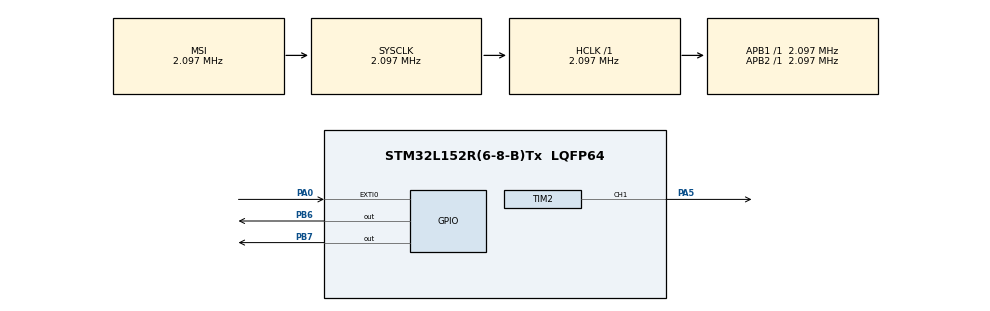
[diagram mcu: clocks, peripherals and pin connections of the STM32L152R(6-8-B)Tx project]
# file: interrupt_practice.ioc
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Mcu.Family=STM32L1
Mcu.Name=STM32L152R(6-8-B)Tx
Mcu.Package=LQFP64
NVIC.EXTI0_IRQn=true\:0\:0\:false\:false\:true\:true
NVIC.PriorityGroup=NVIC_PRIORITYGROUP_4
NVIC.TIM2_IRQn=true\:1\:0\:true\:false\:true\:true
PA0-WKUP1.Signal=GPXTI0
PA5.Signal=S_TIM2_CH1_ETR
PB6.Signal=GPIO_Output
PB7.Signal=GPIO_Output
ProjectManager.HeapSize=0x200
ProjectManager.StackSize=0x400
ProjectManager.TargetToolchain=MDK-ARM V5
RCC.AHBFreq_Value=2097000
RCC.APB1Freq_Value=2097000
RCC.APB2Freq_Value=2097000
RCC.HSE_VALUE=24000000
RCC.HSI_VALUE=16000000
RCC.LSE_VALUE=32768
RCC.MSI_VALUE=2097000
RCC.SYSCLKFreq_VALUE=2097000
RCC.VCOOutputFreq_Value=48000000
SH.S_TIM2_CH1_ETR.0=TIM2_CH1,Output Compare1 CH1
TIM2.Channel-Output\ Compare1\ CH1=TIM_CHANNEL_1
TIM2.Period=10000
TIM2.Prescaler=2000
TIM2.TIM_MasterOutputTrigger=TIM_TRGO_UPDATE
board=custom

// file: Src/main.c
/**
  ******************************************************************************
  * @file           : main.c
  * @brief          : Main program body
  ******************************************************************************
  ** This notice applies to any and all portions of this file
  * that are not between comment pairs USER CODE BEGIN and
  * USER CODE END. Other portions of this file, whether
  * inserted by the user or by software development tools
  * are owned by their respective copyright owners.
  *
  * COPYRIGHT(c) 2019 STMicroelectronics
  *
  * Redistribution and use in source and binary forms, with or without modification,
  * are permitted provided that the following conditions are met:
  *   1. Redistributions of source code must retain the above copyright notice,
  *      this list of conditions and the following disclaimer.
  *   2. Redistributions in binary form must reproduce the above copyright notice,
  *      this list of conditions and the following disclaimer in the documentation
  *      and/or other materials provided with the distribution.
  *   3. Neither the name of STMicroelectronics nor the names of its contributors
  *      may be used to endorse or promote products derived from this software
  *      without specific prior written permission.
  *
  * THIS SOFTWARE IS PROVIDED BY THE COPYRIGHT HOLDERS AND CONTRIBUTORS "AS IS"
  * AND ANY EXPRESS OR IMPLIED WARRANTIES, INCLUDING, BUT NOT LIMITED TO, THE
  * IMPLIED WARRANTIES OF MERCHANTABILITY AND FITNESS FOR A PARTICULAR PURPOSE ARE
  * DISCLAIMED. IN NO EVENT SHALL THE COPYRIGHT HOLDER OR CONTRIBUTORS BE LIABLE
  * FOR ANY DIRECT, INDIRECT, INCIDENTAL, SPECIAL, EXEMPLARY, OR CONSEQUENTIAL
  * DAMAGES (INCLUDING, BUT NOT LIMITED TO, PROCUREMENT OF SUBSTITUTE GOODS OR
  * SERVICES; LOSS OF USE, DATA, OR PROFITS; OR BUSINESS INTERRUPTION) HOWEVER
  * CAUSED AND ON ANY THEORY OF LIABILITY, WHETHER IN CONTRACT, STRICT LIABILITY,
  * OR TORT (INCLUDING NEGLIGENCE OR OTHERWISE) ARISING IN ANY WAY OUT OF THE USE
  * OF THIS SOFTWARE, EVEN IF ADVISED OF THE POSSIBILITY OF SUCH DAMAGE.
  *
  ******************************************************************************
  */
#include "main.h"
#include "stm32l1xx_hal.h"

TIM_HandleTypeDef htim2;

/* USER CODE BEGIN PV */
/* Private variables ---------------------------------------------------------*/

/* USER CODE END PV */

void SystemClock_Config(void);
static void MX_GPIO_Init(void);
static void MX_TIM2_Init(void);
void HAL_TIM_MspPostInit(TIM_HandleTypeDef *htim);

/* USER CODE BEGIN PFP */
/* Private function prototypes -----------------------------------------------*/

/* USER CODE END PFP */

/* USER CODE BEGIN 0 */
uint8_t lyr = 0;
/* USER CODE END 0 */

int main(void)
{

  /* MCU Configuration----------------------------------------------------------*/

  /* Reset of all peripherals, Initializes the Flash interface and the Systick. */
  HAL_Init();

  /* Configure the system clock */
  SystemClock_Config();

  /* Initialize all configured peripherals */
  MX_GPIO_Init();
  MX_TIM2_Init();
  /* USER CODE BEGIN 2 */

	HAL_TIM_Base_Start_IT(&htim2);

  /* USER CODE END 2 */

  /* Infinite loop */
  /* USER CODE BEGIN WHILE */
  while (1)
  {
	HAL_GPIO_TogglePin(GPIOB, GPIO_PIN_7);
	HAL_Delay(500);
  /* USER CODE END WHILE */

  }

}

void SystemClock_Config(void)
{

  RCC_OscInitTypeDef RCC_OscInitStruct;
  RCC_ClkInitTypeDef RCC_ClkInitStruct;

    /**Configure the main internal regulator output voltage
    */
  __HAL_PWR_VOLTAGESCALING_CONFIG(PWR_REGULATOR_VOLTAGE_SCALE1);

    /**Initializes the CPU, AHB and APB busses clocks
    */
  RCC_OscInitStruct.OscillatorType = RCC_OSCILLATORTYPE_MSI;
  RCC_OscInitStruct.MSIState = RCC_MSI_ON;
  RCC_OscInitStruct.MSICalibrationValue = 0;
  RCC_OscInitStruct.MSIClockRange = RCC_MSIRANGE_5;
  RCC_OscInitStruct.PLL.PLLState = RCC_PLL_NONE;
  if (HAL_RCC_OscConfig(&RCC_OscInitStruct) != HAL_OK)
  {
    _Error_Handler(__FILE__, __LINE__);
  }

    /**Initializes the CPU, AHB and APB busses clocks
    */
  RCC_ClkInitStruct.ClockType = RCC_CLOCKTYPE_HCLK|RCC_CLOCKTYPE_SYSCLK
                              |RCC_CLOCKTYPE_PCLK1|RCC_CLOCKTYPE_PCLK2;
  RCC_ClkInitStruct.SYSCLKSource = RCC_SYSCLKSOURCE_MSI;
  RCC_ClkInitStruct.AHBCLKDivider = RCC_SYSCLK_DIV1;
  RCC_ClkInitStruct.APB1CLKDivider = RCC_HCLK_DIV1;
  RCC_ClkInitStruct.APB2CLKDivider = RCC_HCLK_DIV1;

  if (HAL_RCC_ClockConfig(&RCC_ClkInitStruct, FLASH_LATENCY_0) != HAL_OK)
  {
    _Error_Handler(__FILE__, __LINE__);
  }

    /**Configure the Systick interrupt time
    */
  HAL_SYSTICK_Config(HAL_RCC_GetHCLKFreq()/1000);

    /**Configure the Systick
    */
  HAL_SYSTICK_CLKSourceConfig(SYSTICK_CLKSOURCE_HCLK);

  /* SysTick_IRQn interrupt configuration */
  HAL_NVIC_SetPriority(SysTick_IRQn, 0, 0);
}

/* TIM2 init function */
static void MX_TIM2_Init(void)
{

  TIM_MasterConfigTypeDef sMasterConfig;
  TIM_OC_InitTypeDef sConfigOC;

  htim2.Instance = TIM2;
  htim2.Init.Prescaler = 2000;
  htim2.Init.CounterMode = TIM_COUNTERMODE_UP;
  htim2.Init.Period = 10000;
  htim2.Init.ClockDivision = TIM_CLOCKDIVISION_DIV1;
  if (HAL_TIM_OC_Init(&htim2) != HAL_OK)
  {
    _Error_Handler(__FILE__, __LINE__);
  }

  sMasterConfig.MasterOutputTrigger = TIM_TRGO_UPDATE;
  sMasterConfig.MasterSlaveMode = TIM_MASTERSLAVEMODE_DISABLE;
  if (HAL_TIMEx_MasterConfigSynchronization(&htim2, &sMasterConfig) != HAL_OK)
  {
    _Error_Handler(__FILE__, __LINE__);
  }

  sConfigOC.OCMode = TIM_OCMODE_TIMING;
  sConfigOC.Pulse = 0;
  sConfigOC.OCPolarity = TIM_OCPOLARITY_HIGH;
  sConfigOC.OCFastMode = TIM_OCFAST_DISABLE;
  if (HAL_TIM_OC_ConfigChannel(&htim2, &sConfigOC, TIM_CHANNEL_1) != HAL_OK)
  {
    _Error_Handler(__FILE__, __LINE__);
  }

  HAL_TIM_MspPostInit(&htim2);

}

/** Configure pins as
        * Analog
        * Input
        * Output
        * EVENT_OUT
        * EXTI
*/
static void MX_GPIO_Init(void)
{

  GPIO_InitTypeDef GPIO_InitStruct;

  /* GPIO Ports Clock Enable */
  __HAL_RCC_GPIOA_CLK_ENABLE();
  __HAL_RCC_GPIOB_CLK_ENABLE();

  /*Configure GPIO pin Output Level */
  HAL_GPIO_WritePin(GPIOB, GPIO_PIN_6|GPIO_PIN_7, GPIO_PIN_RESET);

  /*Configure GPIO pin : PA0 */
  GPIO_InitStruct.Pin = GPIO_PIN_0;
  GPIO_InitStruct.Mode = GPIO_MODE_IT_RISING;
  GPIO_InitStruct.Pull = GPIO_NOPULL;
  HAL_GPIO_Init(GPIOA, &GPIO_InitStruct);

  /*Configure GPIO pins : PB6 PB7 */
  GPIO_InitStruct.Pin = GPIO_PIN_6|GPIO_PIN_7;
  GPIO_InitStruct.Mode = GPIO_MODE_OUTPUT_PP;
  GPIO_InitStruct.Pull = GPIO_NOPULL;
  GPIO_InitStruct.Speed = GPIO_SPEED_FREQ_LOW;
  HAL_GPIO_Init(GPIOB, &GPIO_InitStruct);

  /* EXTI interrupt init*/
  HAL_NVIC_SetPriority(EXTI0_IRQn, 0, 0);
  HAL_NVIC_EnableIRQ(EXTI0_IRQn);

}

/* USER CODE BEGIN 4 */

void HAL_TIM_PeriodElapsedCallback(TIM_HandleTypeDef *htim)
{

	if(lyr == 7) lyr = 0;
	lyr++;

	for(uint8_t i=0;i<lyr;i++){
		HAL_GPIO_TogglePin(GPIOB,GPIO_PIN_6);
		HAL_Delay(1000);
	}

}

void HAL_GPIO_EXTI_Callback(uint16_t GPIO_Pin)
{
  if(GPIO_Pin == GPIO_PIN_0){

	HAL_GPIO_TogglePin(GPIOB, GPIO_PIN_6);
	for(uint32_t i=0;i<100;i++);
	}
}
/* USER CODE END 4 */

void _Error_Handler(char *file, int line)
{
  while(1)
  {
  }
}

/************************ (C) COPYRIGHT STMicroelectronics *****END OF FILE****/
